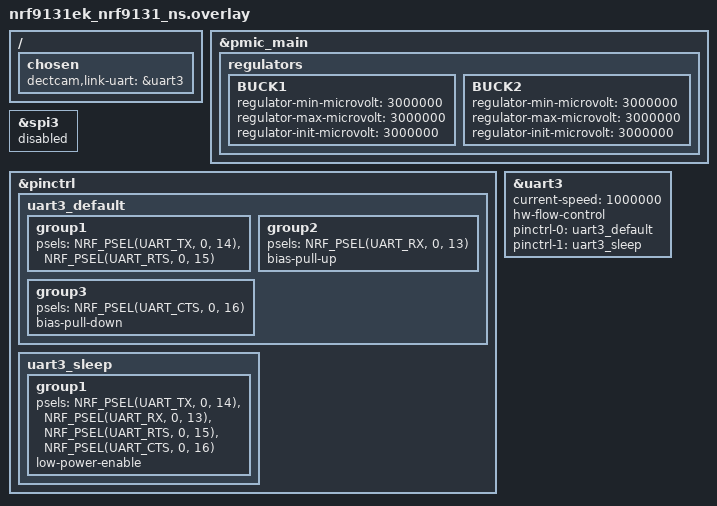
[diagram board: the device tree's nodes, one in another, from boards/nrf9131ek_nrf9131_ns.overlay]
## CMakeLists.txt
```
cmake_minimum_required(VERSION 3.20.0)

find_package(Zephyr REQUIRED HINTS $ENV{ZEPHYR_BASE})

project(dect_cam_tx)

target_sources(app PRIVATE
    src/main.c
    src/radio.c
    src/uart_in.c
    src/camctl.c
    src/ctrl.c
)

# Shared protocol / config headers live one level up, outside this app.
target_include_directories(app PRIVATE ${CMAKE_CURRENT_SOURCE_DIR}/../common)
```

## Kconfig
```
# rsource, not source: plain `source` resolves against $srctree (ZEPHYR_BASE),
# whereas rsource is relative to this file, which is what we want for a
# sibling directory.
rsource "../common/Kconfig.dectcam"

menu "DECT camera transmitter"

config DECTCAM_TX_UART_BAUD
	int "Baud rate of the link from the camera board"
	default 1000000
	help
	  Must match CONFIG_DECTCAM_UART_BAUD on the ESP32. 1 Mbaud is the
	  nRF9151 UARTE maximum.

config DECTCAM_TX_RING_SIZE
	int "Input ring buffer size (bytes)"
	default 8192
	help
	  Buffers packets arriving from the ESP32 while the radio is busy.

	  Deliberately modest: this is live video, so a deep buffer only adds
	  latency. When it overflows the oldest bytes are discarded and the
	  decoder resynchronises on the next packet magic.

config DECTCAM_TX_LBT
	bool "Listen before talk"
	default n
	help
	  Measure channel RSSI before each transmission and skip the slot if
	  the channel is busy.

	  Streaming video is a near-continuous transmit duty cycle, which the
	  NCS DECT samples make no attempt to regulate. Enabling this is a
	  step towards the channel-access behaviour ETSI EN 301 406-2 expects,
	  at the cost of throughput and jitter.

	  It is NOT a completeness claim: this is lab equipment and confirming
	  local compliance remains the operator's responsibility.

config DECTCAM_TX_LBT_THRESHOLD
	int "LBT RSSI threshold (dBm)"
	default -70
	depends on DECTCAM_TX_LBT
	help
	  Channel is considered busy above this level.

config DECTCAM_TX_TEST_PATTERN
	bool "Transmit a generated test pattern instead of UART input"
	default n
	help
	  Emits synthetic frames without needing the ESP32 connected, so the
	  radio link can be brought up and measured on its own. Pairs with the
	  receiver and the PC viewer to validate everything except the camera.

config DECTCAM_TX_TEST_PATTERN_SIZE
	int "Test pattern frame size (bytes)"
	default 6000
	depends on DECTCAM_TX_TEST_PATTERN

config DECTCAM_TX_TEST_PATTERN_FPS
	int "Test pattern frame rate"
	default 10
	depends on DECTCAM_TX_TEST_PATTERN

endmenu

menu "Zephyr Kernel"
source "Kconfig.zephyr"
endmenu
```

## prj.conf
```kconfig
# DECT camera transmitter

CONFIG_TFM_PROFILE_TYPE_MINIMAL=y

# Modem + DECT NR+ PHY
CONFIG_NRF_MODEM_LIB=y
CONFIG_NRF_MODEM_LINK_BINARY_DECT_PHY=y
CONFIG_MODEM_ANTENNA=n

CONFIG_HWINFO=y

# UART link from the camera board. Async so EasyDMA does the work; a polled or
# interrupt-per-byte driver cannot keep up with 1 Mbaud alongside the radio.
CONFIG_SERIAL=y
CONFIG_UART_ASYNC_API=y
CONFIG_RING_BUFFER=y

# The link uart MUST be async, uart0 MUST stay interrupt-driven for the shell.
# The per-instance switches carry the instance number in the symbol name, so
# they live in boards/<board>.conf next to the overlay that chooses the
# instance: the DK uses uart2, the EK uart3.

CONFIG_LOG=y
CONFIG_LOG_BUFFER_SIZE=4096
# Without this Zephyr renders every %f in a log message as the literal
# "*float*", which silently destroys all the rate statistics.
CONFIG_CBPRINTF_FP_SUPPORT=y
# Immediate, not deferred.
#
# With deferred logging plus the shell enabled, nothing at all reached a
# passively captured console -- output only appeared in response to typed
# input. That blinded the whole bring-up: an error at startup was invisible
# and looked like a wiring fault for hours.
#
# Immediate mode costs some latency in the logging call itself, which is an
# easy trade for being able to see what the board is doing.
CONFIG_LOG_MODE_IMMEDIATE=y

# Shell on VCOM0, used to reach the camera over the uart2 back-channel.
#
# The camera board has a console of its own, so this is a convenience rather
# than a necessity: it puts the camera controls on the same terminal as the
# radio statistics, and opening the camera's own port resets it, which throws
# away whatever was set at runtime.
CONFIG_SHELL=y
CONFIG_SHELL_STACK_SIZE=2048
CONFIG_SHELL_PROMPT_UART="dectcam-tx:~$ "
CONFIG_SHELL_CMD_BUFF_SIZE=128
# Route logs through the plain UART backend, NOT through the shell.
#
# With CONFIG_SHELL_LOG_BACKEND=y the periodic statistics stopped appearing on
# a passively captured console -- the shell only emitted output in response to
# input. That is fine interactively but useless when a script is watching the
# port, which is how this project is debugged.
CONFIG_SHELL_LOG_BACKEND=n
CONFIG_LOG_BACKEND_UART=y
# No colour escapes: the console is usually being captured with `cat`, and
# ANSI sequences make those logs painful to read.
CONFIG_SHELL_VT100_COLORS=n

CONFIG_MAIN_STACK_SIZE=4096
CONFIG_SYSTEM_WORKQUEUE_STACK_SIZE=2048

CONFIG_ASSERT=y
CONFIG_RESET_ON_FATAL_ERROR=n
```

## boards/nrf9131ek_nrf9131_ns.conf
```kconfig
# Per-instance UART switches for the nRF9131 EK, where the camera link is uart3.
#
# Instance 2 is not available here: on the nRF91 each instance number is shared
# by SPIM, SPIS, TWIM, TWIS and UARTE, and the EK spends instance 2 on i2c2 for
# the nPM1300 PMIC. Instance 3 is spent on spi3 for an external flash that the
# board already leaves disabled, so the overlay reclaims it.
#
# The nRF UARTE driver picks the mode per instance, and Kconfig says:
#     config UART_3_ASYNC
#         depends on UART_ASYNC_API && !UART_3_INTERRUPT_DRIVEN
#         default y
#
# Enabling the shell turns on CONFIG_UART_INTERRUPT_DRIVEN, which defaults
# UART_3_INTERRUPT_DRIVEN to y and therefore silently disables async on the
# link uart. uart_callback_set() then returns -ENOSYS, uart_in_init() fails and
# main() halts -- while the shell keeps answering from its own thread, so the
# board looks perfectly healthy. That cost a long debugging session on the DK.
CONFIG_UART_3_INTERRUPT_DRIVEN=n
CONFIG_UART_3_ASYNC=y
```

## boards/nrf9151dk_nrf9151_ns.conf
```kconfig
# Per-instance UART switches for the nRF9151 DK, where the camera link is uart2.
#
# These cannot live in prj.conf: the symbol name carries the instance number,
# and the nRF9131 EK has to use uart3 because instance 2 is its PMIC i2c.
#
# The nRF UARTE driver picks the mode per instance, and Kconfig says:
#     config UART_2_ASYNC
#         depends on UART_ASYNC_API && !UART_2_INTERRUPT_DRIVEN
#         default y
#
# Enabling the shell turns on CONFIG_UART_INTERRUPT_DRIVEN, which defaults
# UART_2_INTERRUPT_DRIVEN to y and therefore silently disables async on uart2.
# uart_callback_set() then returns -ENOSYS, uart_in_init() fails and main()
# halts -- while the shell keeps answering from its own thread, so the board
# looks perfectly healthy. That cost a long debugging session.
CONFIG_UART_2_INTERRUPT_DRIVEN=n
CONFIG_UART_2_ASYNC=y
```

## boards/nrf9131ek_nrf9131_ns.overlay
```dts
/*
 * Transmitter on the nRF9131 EK (PCA10165): uart3 routed to the left header
 * for the ESP32-S3 camera link.
 *
 *   P0.13 = RX  (from ESP32-S3 GPIO42)
 *   P0.14 = TX  (to   ESP32-S3 GPIO21)
 *   P0.15 = RTS (to   ESP32-S3 GPIO41 / CTS)
 *   P0.16 = CTS (from ESP32-S3 GPIO47 / RTS)
 *
 * One connector only, as required. The EK breaks out P0.13 to P0.31 on the
 * left header and P0.00 to P0.12 on the right, and the left header carries a
 * GND of its own between P0.13 and P0.14 -- so the whole link, ground
 * included, lands on one side of the board.
 *
 * These four are adjacent and genuinely unused: the board's device tree spends
 * P0.17 and P0.23 to P0.25 on VCOM1, P0.20 to P0.22 and P0.26 on spi3, P0.28
 * on the button and P0.29 to P0.31 on the LEDs. That leaves P0.13 to P0.16,
 * P0.18, P0.19 and P0.27 free on this header; the first four are contiguous.
 *
 * The ESP32-S3 side is unchanged from the nRF9151 DK wiring. Only the pin
 * numbers at this end move, which is the point of keeping this in an overlay.
 *
 * Why uart3 and not uart2 as on the DK
 * ------------------------------------
 * On the nRF91 each peripheral instance number is shared by SPIM, SPIS, TWIM,
 * TWIS and UARTE, so only one of them can exist at a time. Instance 2 is taken
 * here by i2c2, which is how the nPM1300 PMIC is reached, and the PMIC powers
 * the board. Instance 3 is taken by spi3, which exists only for an external
 * flash the board already leaves disabled, so that is the one to reclaim.
 *
 * Flow control
 * -------------
 * On the nRF UARTE, hardware flow control is a single CONFIG.HWFC bit covering
 * RTS *and* CTS -- Zephyr offers no RTS-only mode. We want RTS, so we get CTS
 * whether we like it or not.
 *
 * The pull-down on CTS is deliberate, as on the DK. It costs nothing while the
 * ESP32 drives the line, and if that wire is ever missing the input reads as
 * asserted and the transmitter keeps working, rather than floating and
 * behaving unpredictably.
 *
 * VDD_IO raised to 3.0 V
 * -----------------------
 * The board ships with both nPM1300 buck outputs pinned to 1.8 V, which is
 * fine for the video direction (ESP32 3.3 V into a 1.8 V input, clamped safely
 * by the 1 kOhm series resistors) but not for the return path: the ESP32-S3
 * needs 0.75 x 3.3 V = 2.475 V to read a logic high, and 1.8 V never reaches
 * that. With the camera unplugged, measured on the header VDD pin: 1.8 V at
 * the board's default, 3.0 V with the override below.
 *
 * Both BUCK1 and BUCK2 are moved together. Neither is named, labelled, or
 * connected to a documented consumer anywhere in the board's device tree, so
 * there is no way to tell which one is VDD_IO from the files alone; moving
 * only one risks leaving the SiP under-supplied on whichever rail was guessed
 * wrong. 3.0 V rather than the driver's 3.3 V ceiling matches what the nRF9151
 * DK already runs at and what the ESP32-S3 side already tolerates, keeping a
 * margin to the nPM1300's actual maximum instead of testing at it.
 *
 * This changes the level on every pin fed by this rail, uart3 included, which
 * is the point: it moves this board's camera link onto the same 3.0 V regime
 * as the DK, so the same wiring notes apply unchanged -- the two series
 * resistors on the ESP32-to-nRF lines stay mandatory. See docs/wiring.md.
 */

&pmic_main {
	regulators {
		BUCK1 {
			regulator-min-microvolt = <3000000>;
			regulator-max-microvolt = <3000000>;
			regulator-init-microvolt = <3000000>;
		};

		BUCK2 {
			regulator-min-microvolt = <3000000>;
			regulator-max-microvolt = <3000000>;
			regulator-init-microvolt = <3000000>;
		};
	};
};

/ {
	chosen {
		/* Which instance carries the camera link, so the source does not
		 * have to know. The two boards cannot agree on a number. */
		dectcam,link-uart = &uart3;
	};
};

/* Frees instance 3 for uart3. Only the external flash used it, and that flash
 * is already disabled in the board's device tree. */
&spi3 {
	status = "disabled";
};

&pinctrl {
	uart3_default: uart3_default {
		group1 {
			psels = <NRF_PSEL(UART_TX, 0, 14)>,
				<NRF_PSEL(UART_RTS, 0, 15)>;
		};
		group2 {
			psels = <NRF_PSEL(UART_RX, 0, 13)>;
			bias-pull-up;
		};
		group3 {
			/* Driven by the ESP32-S3; pull-down is the safe fallback. */
			psels = <NRF_PSEL(UART_CTS, 0, 16)>;
			bias-pull-down;
		};
	};

	uart3_sleep: uart3_sleep {
		group1 {
			psels = <NRF_PSEL(UART_TX, 0, 14)>,
				<NRF_PSEL(UART_RX, 0, 13)>,
				<NRF_PSEL(UART_RTS, 0, 15)>,
				<NRF_PSEL(UART_CTS, 0, 16)>;
			low-power-enable;
		};
	};
};

&uart3 {
	status = "okay";
	current-speed = <1000000>;
	hw-flow-control;
	pinctrl-0 = <&uart3_default>;
	pinctrl-1 = <&uart3_sleep>;
	pinctrl-names = "default", "sleep";
};
```

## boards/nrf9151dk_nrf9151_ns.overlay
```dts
/*
 * Transmitter: uart2 routed to the Arduino header for the ESP32-S3 camera link.
 *
 *   P0.02 = Arduino D2 = RX  (from ESP32-S3 GPIO42)
 *   P0.03 = Arduino D3 = TX  (to   ESP32-S3 GPIO21)
 *   P0.06 = Arduino D6 = RTS (to   ESP32-S3 GPIO41 / CTS)
 *   P0.07 = Arduino D7 = CTS (from ESP32-S3 GPIO47 / RTS)
 *
 * uart1 is not used: nrf9151dk_nrf9151_ns.dts disables it because TF-M claims
 * it for secure logging. uart2 is free and the nRF91 pin matrix lets us put
 * it on any pad.
 *
 * P0.00/01/04/05 are LEDs and P0.08/09/18/19 are buttons, so P0.02/03/06/07
 * are the free Arduino-header pins.
 *
 * Flow control
 * -------------
 * On the nRF UARTE, hardware flow control is a single CONFIG.HWFC bit covering
 * RTS *and* CTS -- Zephyr offers no RTS-only mode (see UARTE_NRF_CONFIG in
 * uart_nrfx_uarte.c). We want RTS, so we get CTS whether we like it or not.
 *
 * The previous camera board, an AI-Thinker ESP32-CAM, had no spare boot-safe
 * output pin to drive our CTS, so CTS was parked on P0.07 with an internal
 * pull-down: permanently "clear to send", with D7 required to stay
 * unconnected. The ESP32-S3 has the pin, so this is now a real signal.
 *
 * The pull-down is kept deliberately. It costs nothing while the ESP32 drives
 * the line, and if that wire is ever missing the input reads as asserted and
 * the transmitter keeps working, rather than floating and behaving
 * unpredictably.
 */

/ {
	chosen {
		/* Which instance carries the camera link, so the source does not
		 * have to know. The nRF9131 EK cannot use uart2 -- instance 2 is
		 * its PMIC i2c -- so this is a board property, not an
		 * application one. */
		dectcam,link-uart = &uart2;
	};
};

&pinctrl {
	uart2_default: uart2_default {
		group1 {
			psels = <NRF_PSEL(UART_TX, 0, 3)>,
				<NRF_PSEL(UART_RTS, 0, 6)>;
		};
		group2 {
			psels = <NRF_PSEL(UART_RX, 0, 2)>;
			bias-pull-up;
		};
		group3 {
			/* Driven by the ESP32-S3; pull-down is the safe fallback. */
			psels = <NRF_PSEL(UART_CTS, 0, 7)>;
			bias-pull-down;
		};
	};

	uart2_sleep: uart2_sleep {
		group1 {
			psels = <NRF_PSEL(UART_TX, 0, 3)>,
				<NRF_PSEL(UART_RX, 0, 2)>,
				<NRF_PSEL(UART_RTS, 0, 6)>,
				<NRF_PSEL(UART_CTS, 0, 7)>;
			low-power-enable;
		};
	};
};

&uart2 {
	status = "okay";
	current-speed = <1000000>;
	hw-flow-control;
	pinctrl-0 = <&uart2_default>;
	pinctrl-1 = <&uart2_sleep>;
	pinctrl-names = "default", "sleep";
};
```

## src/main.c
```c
/*
 * main.c - DECT NR+ camera link, transmitter.
 *
 * SPDX-License-Identifier: Apache-2.0
 *
 * Reads dectcam packets from the camera board over uart2 and retransmits each one
 * verbatim as a DECT NR+ PDC. The packet format is chosen so that exactly one
 * packet fits one transport block, so this side never has to parse or
 * re-fragment anything: it is a pure pump.
 *
 * See docs/architecture.md for the whole picture.
 */

#include <zephyr/kernel.h>
#include <zephyr/logging/log.h>
#include <zephyr/drivers/gpio.h>

#include "radio.h"
#include "uart_in.h"
#include "ctrl.h"
#include "dectcam_cfg.h"

LOG_MODULE_REGISTER(dectcam_tx, CONFIG_DECTCAM_LOG_LEVEL);

/* LED0 = radio up, LED1 = TX activity. */
static const struct gpio_dt_spec led_up = GPIO_DT_SPEC_GET(DT_ALIAS(led0), gpios);
static const struct gpio_dt_spec led_tx = GPIO_DT_SPEC_GET(DT_ALIAS(led1), gpios);

static uint8_t pkt_buf[DECTCAM_MAX_PACKET];

static void leds_init(void)
{
	if (gpio_is_ready_dt(&led_up)) {
		gpio_pin_configure_dt(&led_up, GPIO_OUTPUT_INACTIVE);
	}
	if (gpio_is_ready_dt(&led_tx)) {
		gpio_pin_configure_dt(&led_tx, GPIO_OUTPUT_INACTIVE);
	}
}

#if CONFIG_DECTCAM_TX_TEST_PATTERN
/*
 * Synthetic frames so the radio link can be characterised without the camera
 * or the ESP32 attached. The payload is a counting pattern, which makes any
 * corruption obvious in a hex dump at the far end.
 */
#include "dectcam_proto.h"

static int send_test_frame(uint16_t frame_id)
{
	const uint16_t frag_payload = DECTCAM_FRAG_PAYLOAD;
	const uint16_t total = CONFIG_DECTCAM_TX_TEST_PATTERN_SIZE;
	const uint16_t nfrag = (total + frag_payload - 1) / frag_payload;
	static uint8_t body[DECTCAM_MAX_PAYLOAD];
	int sent = 0;

	for (uint16_t i = 0; i < nfrag; i++) {
		const uint16_t chunk =
			MIN(frag_payload, (uint16_t)(total - i * frag_payload));

		for (uint16_t k = 0; k < chunk; k++) {
			body[k] = (uint8_t)(frame_id + i + k);
		}

		const size_t plen = dectcam_encode(pkt_buf, sizeof(pkt_buf),
						   DECTCAM_TYPE_JPEG_FRAG, frame_id, i, nfrag,
						   body, chunk);

		if (plen == 0 || radio_tx(pkt_buf, plen) != 0) {
			return sent;
		}
		sent++;
	}
	return sent;
}
#endif

int main(void)
{
	LOG_INF("DECT camera transmitter starting");

	leds_init();

	if (radio_init() != 0) {
		LOG_ERR("radio init failed; halting");
		return -EIO;
	}
	radio_set_ctrl_cb(ctrl_on_packet);
	gpio_pin_set_dt(&led_up, 1);

#if !CONFIG_DECTCAM_TX_TEST_PATTERN
	if (uart_in_init() != 0) {
		LOG_ERR("uart init failed; halting");
		return -EIO;
	}
#else
	LOG_WRN("TEST PATTERN mode: uart input is not used");
#endif

	int64_t last_stats = k_uptime_get();
	uint32_t tx_since = 0;
	uint64_t bytes_since = 0;

#if CONFIG_DECTCAM_TX_TEST_PATTERN
	uint16_t frame_id = 0;
	const int64_t period_ms = 1000 / CONFIG_DECTCAM_TX_TEST_PATTERN_FPS;
#endif

	for (;;) {
#if CONFIG_DECTCAM_TX_TEST_PATTERN
		const int64_t t0 = k_uptime_get();
		int n = send_test_frame(frame_id++);

		tx_since += n;
		bytes_since += (uint64_t)n * DECTCAM_TBS_BYTES;
		gpio_pin_toggle_dt(&led_tx);

		const int64_t spent = k_uptime_get() - t0;

		if (spent < period_ms) {
			k_msleep(period_ms - spent);
		}
#else
		/*
		 * Listen for control before touching the radio for video, so
		 * the receive window never lands in the middle of a burst.
		 */
		ctrl_poll();

		/*
		 * Slip any pending acknowledgement into the stream. It is an
		 * ordinary packet as far as everything downstream is
		 * concerned, and it rides the direction that already works.
		 */
		{
			uint8_t ack[DECTCAM_CTRL_LEN + DECTCAM_OVERHEAD];
			const size_t n = ctrl_pending_ack(ack, sizeof(ack));

			if (n > 0) {
				radio_tx(ack, n);
			}
		}

		/*
		 * Announce the radio settings once a second, for the same
		 * reason the camera announces its own: they change at run time
		 * now, and a viewer that attaches later has no other way to
		 * learn where the link ended up.
		 */
		{
			static int64_t last_cfg;
			const int64_t t = k_uptime_get();

			if (t - last_cfg >= 1000) {
				struct radio_cfg rc;
				struct dectcam_radio_cfg body;
				uint8_t buf[DECTCAM_RADIO_CFG_LEN + DECTCAM_OVERHEAD];
				uint8_t packed[DECTCAM_RADIO_CFG_LEN];

				last_cfg = t;
				radio_get_cfg(&rc);
				body.carrier = rc.carrier;
				body.mcs = rc.mcs;
				body.tx_power = rc.tx_power;
				body.subslots = rc.subslots;
				body.reserved = 0;
				body.frag_payload = rc.frag_payload;
				dectcam_radio_cfg_pack(packed, &body);

				const size_t n = dectcam_encode(
					buf, sizeof(buf), DECTCAM_TYPE_RADIO_CFG, 0, 0, 0,
					packed, sizeof(packed));

				if (n > 0) {
					radio_tx(buf, n);
				}
			}
		}

		int len = uart_in_get_packet(pkt_buf, sizeof(pkt_buf), 100);

		if (len > 0) {
			if (radio_tx(pkt_buf, len) == 0) {
				tx_since++;
				bytes_since += len;
				/*
				 * Toggling per packet would be a blur; every
				 * 16 gives a visible flicker that tracks
				 * activity.
				 */
				if ((tx_since & 0x0f) == 0) {
					gpio_pin_toggle_dt(&led_tx);
				}
			}
		}
#endif

#if CONFIG_DECTCAM_STATS_INTERVAL_MS > 0
		const int64_t now = k_uptime_get();

		if (now - last_stats >= CONFIG_DECTCAM_STATS_INTERVAL_MS) {
			const double secs = (now - last_stats) / 1000.0;
			struct radio_stats rs;

			radio_get_stats(&rs);

#if CONFIG_DECTCAM_TX_TEST_PATTERN
			LOG_INF("tx %.1f pkt/s, %.1f kB/s | ok %u err %u lbt_busy %u",
				tx_since / secs, bytes_since / secs / 1000.0, rs.tx_ok,
				rs.tx_err, rs.tx_lbt_busy);
#else
			struct uart_in_stats us;

			uart_in_get_stats(&us);
			LOG_INF("tx %.1f pkt/s, %.1f kB/s | radio ok %u err %u lbt %u | "
				"uart pkt %u crc %u resync %u ovr %u",
				tx_since / secs, bytes_since / secs / 1000.0, rs.tx_ok,
				rs.tx_err, rs.tx_lbt_busy, us.packets, us.crc_err, us.resyncs,
				us.overruns);
#endif
			tx_since = 0;
			bytes_since = 0;
			last_stats = now;
		}
#endif
	}

	return 0;
}
```

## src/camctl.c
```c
/*
 * camctl.c - shell command that forwards text to the camera board.
 *
 * SPDX-License-Identifier: Apache-2.0
 *
 * The uart link to the camera is full duplex: the camera sends video packets
 * on its TX line, and its RX line (our P0.03 -> ESP32-S3 GPIO21) would
 * otherwise be idle. This puts it to work as a control channel, so camera
 * parameters can be changed from the transmitter's own console.
 *
 * The camera board has a console of its own, so this is a convenience rather
 * than a necessity -- but a real one: it puts the camera controls on the same
 * terminal as the radio statistics, and opening the camera's own port resets
 * the board, which throws away whatever was set at runtime.
 *
 * No reply comes back: the return direction carries the video stream and must
 * not be polluted with text. Confirmation arrives instead as a FRAME_META
 * packet, which the PC viewer displays.
 */

#include <zephyr/kernel.h>
#include <zephyr/shell/shell.h>
#include <zephyr/device.h>
#include <zephyr/drivers/uart.h>
#include <zephyr/logging/log.h>

#include "radio.h"
#include "uart_in.h"
#include "camctl.h"

LOG_MODULE_DECLARE(dectcam_tx, CONFIG_DECTCAM_LOG_LEVEL);

/*
 * The camera's resolution table, in the order the wire protocol indexes it.
 * Must match s_sizes[] in the camera firmware and RESOLUTIONS in the viewer;
 * the protocol self-tests pin the order down on both of those.
 */
static const char *const res_names[] = {
	"qqvga", "qcif", "hqvga", "qvga", "cif", "hvga", "vga", "svga",
};

const char *camctl_res_name(uint8_t index)
{
	if (index >= ARRAY_SIZE(res_names)) {
		return NULL;
	}
	return res_names[index];
}

/*
 * Put one line on the wire.
 *
 * Delegated to uart_in, which owns the device and its callback. This used to
 * use uart_poll_out() directly, on the reasoning that a dozen bytes at 1 Mbaud
 * is too short to be worth DMA. That was wrong for a subtler reason: the
 * receive side holds the UART open with the async API, and poll_out alongside
 * it loses characters. "cam fps 15" reached the camera as "cam fps 1".
 */
static int write_line(const char *line)
{
	return uart_in_send_line(line);
}

static int send_line(const struct shell *sh, const char *line)
{
	int err = write_line(line);

	if (err == -ENODEV) {
		shell_error(sh, "link uart not ready");
	}
	return err;
}

int camctl_send_res(uint8_t index)
{
	const char *name = camctl_res_name(index);
	char line[32];

	if (name == NULL) {
		return -EINVAL;
	}
	snprintk(line, sizeof(line), "cam res %s", name);
	LOG_INF("camera: %s", line);
	return write_line(line);
}

int camctl_send_fps(uint8_t fps)
{
	char line[32];

	if (fps < 1 || fps > 30) {
		return -EINVAL;
	}
	snprintk(line, sizeof(line), "cam fps %u", fps);
	LOG_INF("camera: %s", line);
	return write_line(line);
}

int camctl_send_quality(uint8_t q)
{
	char line[32];

	if (q < 4 || q > 63) {
		return -EINVAL;
	}
	snprintk(line, sizeof(line), "cam quality %u", q);
	LOG_INF("camera: %s", line);
	return write_line(line);
}

static int cmd_cam(const struct shell *sh, size_t argc, char **argv)
{
	char line[96];
	size_t off = 0;

	if (argc < 2) {
		shell_print(sh, "usage: cam <res|quality|fps|vflip|hmirror|pause|resume|info> "
				"[value]");
		shell_print(sh, "  res      qqvga qcif hqvga qvga cif hvga vga svga");
		shell_print(sh, "  quality  4..63 (LOWER is better quality, bigger frames)");
		shell_print(sh, "  fps      1..30");
		shell_print(sh, "");
		shell_print(sh, "The camera does not reply on this wire; watch the viewer's");
		shell_print(sh, "FRAME_META readout to confirm the change took effect.");
		return -EINVAL;
	}

	/* Rebuild "cam <args...>" for the far end. */
	off = snprintk(line, sizeof(line), "cam");
	for (size_t i = 1; i < argc; i++) {
		int n = snprintk(&line[off], sizeof(line) - off, " %s", argv[i]);

		if (n < 0 || (size_t)n >= sizeof(line) - off) {
			shell_error(sh, "command too long");
			return -EINVAL;
		}
		off += n;
	}

	if (send_line(sh, line) != 0) {
		return -EIO;
	}
	shell_print(sh, "sent to camera: %s", line);
	return 0;
}

static int cmd_camraw(const struct shell *sh, size_t argc, char **argv)
{
	if (argc < 2) {
		shell_print(sh, "usage: camraw <text>   (sent verbatim, newline appended)");
		return -EINVAL;
	}

	char line[96];
	size_t off = 0;

	for (size_t i = 1; i < argc; i++) {
		int n = snprintk(&line[off], sizeof(line) - off, i == 1 ? "%s" : " %s", argv[i]);

		if (n < 0 || (size_t)n >= sizeof(line) - off) {
			shell_error(sh, "command too long");
			return -EINVAL;
		}
		off += n;
	}

	if (send_line(sh, line) != 0) {
		return -EIO;
	}
	shell_print(sh, "sent to camera: %s", line);
	return 0;
}

/*
 * On-demand status. Deliberately independent of the logging subsystem: when
 * logs are misconfigured or a capture is passive, this still answers.
 */
static int cmd_dectstat(const struct shell *sh, size_t argc, char **argv)
{
	ARG_UNUSED(argc);
	ARG_UNUSED(argv);

	struct radio_stats rs;
	struct uart_in_stats us;

	radio_get_stats(&rs);
	uart_in_get_stats(&us);

	shell_print(sh, "device id     : %u", radio_device_id());
	shell_print(sh, "-- uart from camera --");
	shell_print(sh, "  packets     : %u", us.packets);
	shell_print(sh, "  bytes       : %llu", (unsigned long long)us.bytes);
	shell_print(sh, "  crc errors  : %u", us.crc_err);
	shell_print(sh, "  resyncs     : %u", us.resyncs);
	shell_print(sh, "  overruns    : %u", us.overruns);
	shell_print(sh, "-- radio --");
	shell_print(sh, "  tx ok       : %u", rs.tx_ok);
	shell_print(sh, "  tx err      : %u", rs.tx_err);
	shell_print(sh, "  lbt busy    : %u", rs.tx_lbt_busy);
	shell_print(sh, "  tx bytes    : %llu", (unsigned long long)rs.tx_bytes);

	if (us.bytes == 0) {
		shell_warn(sh, "");
		shell_warn(sh, "No bytes at all from the camera. Check that it is powered");
		shell_warn(sh, "and that GPIO42 reaches P0.02 (Arduino D2).");
		shell_warn(sh, "If the camera reports 'link stalled', it is being held off");
		shell_warn(sh, "by flow control: check GPIO41 against P0.06 (Arduino D6).");
	}
	return 0;
}

SHELL_CMD_ARG_REGISTER(cam, NULL, "Control the camera over the uart back-channel",
		       cmd_cam, 1, 8);
SHELL_CMD_ARG_REGISTER(camraw, NULL, "Send a raw line to the camera", cmd_camraw, 1, 8);
SHELL_CMD_REGISTER(dectstat, NULL, "Transmitter link and radio counters", cmd_dectstat);
```

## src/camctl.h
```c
/*
 * camctl.h - forward commands to the camera over the UART back-channel.
 *
 * SPDX-License-Identifier: Apache-2.0
 *
 * The same wire that carries video also carries text the other way. These
 * entry points exist so that control telegrams arriving over the air can be
 * passed on without going through the shell.
 *
 * Nothing comes back: the return direction is the video stream and must stay
 * clean. Confirmation reaches the operator as a FRAME_META packet announcing
 * the camera's new settings, which the viewer displays.
 */

#ifndef DECTCAM_TX_CAMCTL_H
#define DECTCAM_TX_CAMCTL_H

#include <stdint.h>

/*
 * Resolution by index into the camera's own table. An index is used rather
 * than a name because it is what travels on the wire; the order is fixed and
 * is checked by the protocol self-tests on both sides.
 */
int camctl_send_res(uint8_t index);

/* 1..30. */
int camctl_send_fps(uint8_t fps);

/* 4..63, lower is better quality and larger frames. */
int camctl_send_quality(uint8_t q);

/* The resolution names, in wire order. NULL if the index is out of range. */
const char *camctl_res_name(uint8_t index);

#endif /* DECTCAM_TX_CAMCTL_H */
```

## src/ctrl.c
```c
/*
 * ctrl.c - control telegrams received over the air, transmitter side.
 *
 * SPDX-License-Identifier: Apache-2.0
 *
 * The operator drives everything from the PC, which is attached to the
 * receiver. Commands therefore travel against the video: PC -> receiver ->
 * air -> here. Anything aimed at the camera is passed on over the UART
 * back-channel that already exists for that purpose.
 *
 * Two things shape the design:
 *
 *   - There is one radio, and it is busy pushing video. Listening means not
 *     transmitting, so the window is short and infrequent, and the sender has
 *     to repeat a telegram until one lands. Repetition is made safe by the
 *     sequence number: a telegram already acted on is counted and ignored.
 *
 *   - Changing the carrier moves the link itself. If only one end moves, the
 *     link is gone and no further command can reach anyone. That case is
 *     handled by moving on trial and returning automatically -- see below.
 */

#include <zephyr/kernel.h>
#include <zephyr/logging/log.h>

#include "ctrl.h"
#include "radio.h"
#include "camctl.h"
#include "dectcam_cfg.h"

LOG_MODULE_DECLARE(dectcam_tx, CONFIG_DECTCAM_LOG_LEVEL);

/*
 * How often to stop transmitting and listen, and for how long.
 *
 * 30 ms out of every 200 costs 15 % of the air time. That sounds like a lot,
 * but the link runs at about half the capacity it has, so it costs no frames
 * in practice -- and it has to be this generous: the far end sends its copies
 * 25 ms apart, so a window narrower than that could fall between two of them
 * and hear nothing at all.
 */
#define LISTEN_PERIOD_MS 200
#define LISTEN_MS        30

/*
 * Carrier change, and why it is done the way it is.
 *
 * The receiver announces the new carrier on the OLD one, then moves. This side
 * moves as soon as it has acknowledged. From that moment the link is unproven:
 * if the receiver never arrives -- wrong channel, interference, a command that
 * was corrupted into a different number -- nothing more can be said to either
 * end, and the only recovery would be a power cycle.
 *
 * So the move is on trial. The receiver confirms with CARRIER_OK once it is
 * actually seeing video on the new carrier. If that confirmation does not
 * arrive in time, this side returns to the previous carrier on its own. The
 * receiver runs the same rollback on a shorter deadline, so the two converge
 * on the old carrier rather than crossing over.
 */
#define CARRIER_TRIAL_MS 6000

static struct ctrl_stats s_stats;

/* Last sequence acted on, so repeats are free of side effects. */
static bool s_have_last_seq;
static uint8_t s_last_seq;

/*
 * Acknowledgement waiting to be slipped into the video stream.
 *
 * Repeated on a clock rather than a count, and for longer than feels
 * necessary, because of when it has to arrive: the far end transmits its
 * command as a one-second burst, and while it is transmitting it is deaf. An
 * acknowledgement sent promptly -- which is what happens, since the command is
 * applied on the first copy that lands -- is therefore usually sent straight
 * into that deafness. Repeating for well past the end of the burst is what
 * makes it land.
 */
#define ACK_REPEAT_MS 150
#define ACK_FOR_MS    2500

static bool s_ack_pending;
static uint8_t s_ack_seq;
static uint8_t s_ack_status;
static int64_t s_ack_until;
static int64_t s_ack_next;

/* Carrier trial state. */
static bool s_carrier_trial;
static uint16_t s_carrier_previous;
static int64_t s_carrier_deadline;

static int64_t s_next_listen;

static void queue_ack(uint8_t seq, uint8_t status)
{
	const int64_t now = k_uptime_get();

	s_ack_pending = true;
	s_ack_seq = seq;
	s_ack_status = status;
	s_ack_until = now + ACK_FOR_MS;
	s_ack_next = now;
}

static uint8_t apply(uint8_t opcode, uint32_t arg)
{
	switch (opcode) {
	case DECTCAM_CTRL_SET_TX_POWER:
		return radio_set_tx_power((uint8_t)arg) == 0
			       ? DECTCAM_ACK_OK
			       : DECTCAM_ACK_BAD_ARG;

	case DECTCAM_CTRL_SET_MCS:
		return radio_set_mcs((uint8_t)arg) == 0
			       ? DECTCAM_ACK_OK
			       : DECTCAM_ACK_BAD_ARG;

	case DECTCAM_CTRL_SET_CARRIER: {
		struct radio_cfg cfg;

		radio_get_cfg(&cfg);
		if (arg == 0 || arg > 0xffff) {
			return DECTCAM_ACK_BAD_ARG;
		}
		if ((uint16_t)arg == cfg.carrier) {
			return DECTCAM_ACK_OK;
		}

		s_carrier_previous = cfg.carrier;
		if (radio_set_carrier((uint16_t)arg) != 0) {
			return DECTCAM_ACK_FAILED;
		}
		s_carrier_trial = true;
		s_carrier_deadline = k_uptime_get() + CARRIER_TRIAL_MS;
		s_stats.carrier_moves++;
		LOG_WRN("carrier %u -> %u on trial; returning in %d ms unless confirmed",
			s_carrier_previous, (uint16_t)arg, CARRIER_TRIAL_MS);
		return DECTCAM_ACK_OK;
	}

	case DECTCAM_CTRL_CARRIER_OK:
		if (s_carrier_trial) {
			s_carrier_trial = false;
			LOG_INF("carrier confirmed by the receiver");
		}
		return DECTCAM_ACK_OK;

	/* Everything below belongs to the camera, not the radio. */
	case DECTCAM_CTRL_SET_RES:
		return camctl_send_res((uint8_t)arg) == 0 ? DECTCAM_ACK_OK
							  : DECTCAM_ACK_BAD_ARG;
	case DECTCAM_CTRL_SET_FPS:
		return camctl_send_fps((uint8_t)arg) == 0 ? DECTCAM_ACK_OK
							  : DECTCAM_ACK_BAD_ARG;
	case DECTCAM_CTRL_SET_QUALITY:
		return camctl_send_quality((uint8_t)arg) == 0 ? DECTCAM_ACK_OK
							      : DECTCAM_ACK_BAD_ARG;

	case DECTCAM_CTRL_NOP:
		return DECTCAM_ACK_OK;

	default:
		return DECTCAM_ACK_UNSUPP;
	}
}

/*
 * Telegram waiting to be acted on.
 *
 * ctrl_on_packet() runs in the modem's event callback -- interrupt context --
 * and must do as little as possible there. Applying a telegram means writing
 * to a UART and logging, neither of which belongs in an interrupt: doing it
 * there truncated a "cam fps 15" into "cam fps 1", which the camera dutifully
 * obeyed.
 *
 * So the callback only parks the telegram, and ctrl_poll() applies it from the
 * main loop. One slot is enough: telegrams arrive at human speed and repeats
 * of the same one are collapsed by the sequence check anyway.
 */
static volatile bool s_inbox_full;
static struct dectcam_ctrl s_inbox;

void ctrl_on_packet(const uint8_t *data, size_t len)
{
	struct dectcam_pkt pkt;
	size_t consumed;

	if (dectcam_decode(data, len, &pkt, &consumed) != DECTCAM_OK) {
		return;
	}
	if (pkt.type != DECTCAM_TYPE_CTRL || pkt.payload_len < DECTCAM_CTRL_LEN) {
		return;
	}
	if (s_inbox_full) {
		/* Still working on the previous one; this is almost certainly a
		 * repeat of it, and the far end will send it again. */
		return;
	}

	dectcam_ctrl_unpack(pkt.payload, &s_inbox);
	s_inbox_full = true;
}

static void process_inbox(void)
{
	if (!s_inbox_full) {
		return;
	}

	const struct dectcam_ctrl c = s_inbox;

	s_inbox_full = false;

	/*
	 * A repeat of something already done. Acknowledge it again -- the
	 * previous acknowledgement evidently did not get through, or the far
	 * end would have stopped repeating -- but do not act on it twice.
	 */
	if (s_have_last_seq && c.seq == s_last_seq) {
		s_stats.duplicates++;
		queue_ack(c.seq, DECTCAM_ACK_OK);
		return;
	}

	const uint8_t status = apply(c.opcode, c.arg32);

	s_have_last_seq = true;
	s_last_seq = c.seq;

	if (status == DECTCAM_ACK_OK) {
		s_stats.applied++;
	} else {
		s_stats.rejected++;
		LOG_WRN("control opcode %u arg %u rejected: status %u", c.opcode,
			(unsigned)c.arg32, status);
	}
	queue_ack(c.seq, status);
}

void ctrl_poll(void)
{
	const int64_t now = k_uptime_get();

	process_inbox();

	/* Carrier trial expired without confirmation: go back. */
	if (s_carrier_trial && now >= s_carrier_deadline) {
		s_carrier_trial = false;
		s_stats.carrier_rollbacks++;
		LOG_ERR("carrier not confirmed; returning to %u", s_carrier_previous);
		radio_set_carrier(s_carrier_previous);
	}

	if (now < s_next_listen) {
		return;
	}
	s_next_listen = now + LISTEN_PERIOD_MS;

	radio_listen(LISTEN_MS);
}

size_t ctrl_pending_ack(uint8_t *out, size_t cap)
{
	if (!s_ack_pending) {
		return 0;
	}

	const int64_t now = k_uptime_get();

	if (now >= s_ack_until) {
		s_ack_pending = false;
		return 0;
	}
	if (now < s_ack_next) {
		return 0;
	}
	s_ack_next = now + ACK_REPEAT_MS;

	const size_t n = dectcam_encode_ctrl(out, cap, DECTCAM_CTRL_ACK, s_ack_seq,
					     s_ack_status);

	if (n == 0) {
		s_ack_pending = false;
	}
	return n;
}

void ctrl_get_stats(struct ctrl_stats *out)
{
	if (out) {
		*out = s_stats;
	}
}
```

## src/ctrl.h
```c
/*
 * ctrl.h - control telegrams received over the air, transmitter side.
 *
 * SPDX-License-Identifier: Apache-2.0
 */

#ifndef DECTCAM_TX_CTRL_H
#define DECTCAM_TX_CTRL_H

#include <stdbool.h>
#include <stdint.h>
#include <stddef.h>

/* Hand a packet received during a listen window to the control logic. */
void ctrl_on_packet(const uint8_t *data, size_t len);

/*
 * Give the control logic a slice of the main loop.
 *
 * Opens a listen window when one is due, applies anything that arrived, and
 * runs the carrier rollback timer. Returns the number of milliseconds the
 * caller should not transmit for, which is zero unless a window is open.
 */
void ctrl_poll(void);

/*
 * Fill `out` with the acknowledgement that is waiting to go into the video
 * stream, if any. Returns its length, or 0 when there is nothing to send.
 *
 * Acknowledgements travel with the video because that direction already
 * exists and already works; adding a second radio turnaround for them would
 * cost air time for no benefit.
 */
size_t ctrl_pending_ack(uint8_t *out, size_t cap);

struct ctrl_stats {
	uint32_t applied;
	uint32_t duplicates;   /* repeats of a telegram already acted on */
	uint32_t rejected;
	uint32_t carrier_moves;
	uint32_t carrier_rollbacks;
};

void ctrl_get_stats(struct ctrl_stats *out);

#endif /* DECTCAM_TX_CTRL_H */
```

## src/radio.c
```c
/*
 * radio.c - DECT NR+ PHY transmit wrapper.
 *
 * SPDX-License-Identifier: Apache-2.0
 *
 * Thin layer over nrf_modem_dect_phy: bring-up sequence, then one blocking
 * transmit call. Structured after the NCS hello_dect sample, which is the
 * reference for what this modem firmware accepts.
 */

#include <zephyr/kernel.h>
#include <zephyr/logging/log.h>
#include <zephyr/drivers/hwinfo.h>

#include <nrf_modem_dect_phy.h>
#include <modem/nrf_modem_lib.h>

#include "radio.h"
#include "dectcam_cfg.h"

LOG_MODULE_REGISTER(radio, CONFIG_DECTCAM_LOG_LEVEL);

BUILD_ASSERT(CONFIG_DECTCAM_CARRIER != 0,
	     "CONFIG_DECTCAM_CARRIER must be set according to local regulations");

static uint16_t s_device_id;
static struct radio_stats s_stats;
static radio_ctrl_cb_t s_ctrl_cb;

/*
 * Live radio parameters, seeded from Kconfig.
 *
 * They were compile-time constants until control from the receiver was added.
 * Keeping them in one struct makes it obvious that the transport block size
 * and the fragment size are derived quantities that must be recomputed
 * whenever the MCS moves -- getting that wrong means the modem silently
 * rejects every transmit.
 */
static struct radio_cfg s_cfg = {
	.carrier = CONFIG_DECTCAM_CARRIER,
	.mcs = CONFIG_DECTCAM_MCS,
	.tx_power = CONFIG_DECTCAM_TX_POWER,
	.subslots = CONFIG_DECTCAM_PACKET_LEN_SUBSLOTS,
	.tbs_bytes = DECTCAM_TBS_BYTES,
	.frag_payload = DECTCAM_FRAG_PAYLOAD,
};

/* Signalled when an asynchronous PHY operation finishes. */
static K_SEM_DEFINE(op_sem, 0, 1);
/* Result of the operation that just completed. */
static volatile int s_op_err;

static bool s_fatal;

#define TX_HANDLE 0u
#define RX_HANDLE 1u
#define OP_TIMEOUT K_MSEC(500)

static void handle_common(int err)
{
	s_op_err = err;
	k_sem_give(&op_sem);
}

static void dect_phy_event_handler(const struct nrf_modem_dect_phy_event *evt)
{
	switch (evt->id) {
	case NRF_MODEM_DECT_PHY_EVT_INIT:
		if (evt->init.err) {
			LOG_ERR("PHY init failed: %d", evt->init.err);
			s_fatal = true;
		}
		handle_common(evt->init.err);
		break;
	case NRF_MODEM_DECT_PHY_EVT_CONFIGURE:
		if (evt->configure.err) {
			LOG_ERR("PHY configure failed: %d", evt->configure.err);
			s_fatal = true;
		}
		handle_common(evt->configure.err);
		break;
	case NRF_MODEM_DECT_PHY_EVT_ACTIVATE:
		if (evt->activate.err) {
			LOG_ERR("PHY activate failed: %d", evt->activate.err);
			s_fatal = true;
		}
		handle_common(evt->activate.err);
		break;
	case NRF_MODEM_DECT_PHY_EVT_COMPLETED:
		handle_common(evt->op_complete.err);
		break;
	case NRF_MODEM_DECT_PHY_EVT_CANCELED:
		handle_common(evt->cancel.err);
		break;
	case NRF_MODEM_DECT_PHY_EVT_DEACTIVATE:
	case NRF_MODEM_DECT_PHY_EVT_DEINIT:
		handle_common(0);
		break;
	case NRF_MODEM_DECT_PHY_EVT_PDC:
		/*
		 * Only ever arrives during a listen window, and the only thing
		 * anyone sends this way is control. Hand it straight over; the
		 * callback must not call back into the modem.
		 */
		s_stats.ctrl_rx++;
		if (s_ctrl_cb) {
			s_ctrl_cb((const uint8_t *)evt->pdc.data, evt->pdc.len);
		}
		break;
	case NRF_MODEM_DECT_PHY_EVT_PCC:
	case NRF_MODEM_DECT_PHY_EVT_PCC_ERROR:
	case NRF_MODEM_DECT_PHY_EVT_PDC_ERROR:
		/* Nothing to do: a missed control frame is simply repeated. */
		break;

	case NRF_MODEM_DECT_PHY_EVT_REJECT:
		LOG_WRN("operation rejected");
		break;
	default:
		/* Capability/band/time/RSSI queries are not used here. */
		break;
	}
}

/* Run one bring-up step and wait for its completion event. */
static int step(const char *what, int err)
{
	if (err) {
		LOG_ERR("%s returned %d", what, err);
		return err;
	}
	if (k_sem_take(&op_sem, K_SECONDS(5)) != 0) {
		LOG_ERR("%s timed out waiting for its event", what);
		return -ETIMEDOUT;
	}
	if (s_fatal) {
		return -EIO;
	}
	return s_op_err;
}

int radio_init(void)
{
	int err;

	err = nrf_modem_lib_init();
	if (err) {
		LOG_ERR("nrf_modem_lib_init failed: %d", err);
		return err;
	}

	err = nrf_modem_dect_phy_event_handler_set(dect_phy_event_handler);
	if (err) {
		LOG_ERR("event_handler_set failed: %d", err);
		return err;
	}

	err = step("dect_phy_init", nrf_modem_dect_phy_init());
	if (err) {
		return err;
	}

	struct nrf_modem_dect_phy_config_params cfg = {
		.band_group_index = CONFIG_DECTCAM_BAND_GROUP_INDEX,
		.harq_rx_process_count = 4,
		.harq_rx_expiry_time_us = 5000000,
	};

	err = step("dect_phy_configure", nrf_modem_dect_phy_configure(&cfg));
	if (err) {
		return err;
	}

	err = step("dect_phy_activate",
		   nrf_modem_dect_phy_activate(NRF_MODEM_DECT_PHY_RADIO_MODE_LOW_LATENCY));
	if (err) {
		return err;
	}

	hwinfo_get_device_id((void *)&s_device_id, sizeof(s_device_id));

	LOG_INF("DECT PHY up: device id %u, carrier %d, MCS %d, %d subslots "
		"(%d B TBS, %d B payload, %d us air time), TX power idx %d",
		s_device_id, CONFIG_DECTCAM_CARRIER, CONFIG_DECTCAM_MCS,
		CONFIG_DECTCAM_PACKET_LEN_SUBSLOTS, DECTCAM_TBS_BYTES, DECTCAM_FRAG_PAYLOAD,
		DECTCAM_AIRTIME_US, CONFIG_DECTCAM_TX_POWER);

	return 0;
}

int radio_tx(const uint8_t *data, size_t len)
{
	if (len == 0 || len > (size_t)s_cfg.tbs_bytes) {
		return -EINVAL;
	}

	struct dectcam_phy_hdr_type1 hdr = {
		.header_format = 0,
		.packet_length_type = 0, /* subslots */
		.packet_length = (uint8_t)(s_cfg.subslots - 1),
		.short_network_id = (CONFIG_DECTCAM_NETWORK_ID & 0xff),
		.transmitter_id_hi = (s_device_id >> 8),
		.transmitter_id_lo = (s_device_id & 0xff),
		.transmit_power = s_cfg.tx_power,
		.reserved = 0,
		.df_mcs = s_cfg.mcs,
	};

	struct nrf_modem_dect_phy_tx_params tx = {
		.start_time = 0, /* as soon as possible */
		.handle = TX_HANDLE,
		.network_id = CONFIG_DECTCAM_NETWORK_ID,
		.phy_type = 0,
		.carrier = s_cfg.carrier,
		.phy_header = (union nrf_modem_dect_phy_hdr *)&hdr,
		.data = (void *)data,
		.data_size = len,
#if CONFIG_DECTCAM_TX_LBT
		.lbt_rssi_threshold_max = CONFIG_DECTCAM_TX_LBT_THRESHOLD,
		.lbt_period = NRF_MODEM_DECT_LBT_PERIOD_MAX,
#else
		/* lbt_period 0 disables listen-before-talk entirely. */
		.lbt_rssi_threshold_max = 0,
		.lbt_period = 0,
#endif
	};

	int err = nrf_modem_dect_phy_tx(&tx);

	if (err) {
		s_stats.tx_err++;
		return err;
	}

	/*
	 * Wait for completion. Without this the next call could be issued
	 * while the modem still owns `data`, and the modem would reject the
	 * operation anyway once its queue filled.
	 */
	if (k_sem_take(&op_sem, OP_TIMEOUT) != 0) {
		s_stats.tx_err++;
		LOG_WRN("TX completion timed out");
		return -ETIMEDOUT;
	}

	if (s_op_err) {
		if (s_op_err == NRF_MODEM_DECT_PHY_ERR_LBT_CHANNEL_BUSY) {
			s_stats.tx_lbt_busy++;
		} else {
			s_stats.tx_err++;
			LOG_WRN("TX completed with error %d", s_op_err);
		}
		return -EIO;
	}

	s_stats.tx_ok++;
	s_stats.tx_bytes += len;
	return 0;
}

int radio_listen(uint32_t ms)
{
	struct nrf_modem_dect_phy_rx_params rx = {
		.start_time = 0,
		.handle = RX_HANDLE,
		.network_id = CONFIG_DECTCAM_NETWORK_ID,
		.mode = NRF_MODEM_DECT_PHY_RX_MODE_CONTINUOUS,
		.rssi_interval = NRF_MODEM_DECT_PHY_RSSI_INTERVAL_OFF,
		.link_id = NRF_MODEM_DECT_PHY_LINK_UNSPECIFIED,
		.rssi_level = -60,
		.carrier = s_cfg.carrier,
		.duration = ms * NRF_MODEM_DECT_MODEM_TIME_TICK_RATE_KHZ,
		.filter.short_network_id = CONFIG_DECTCAM_NETWORK_ID & 0xff,
		.filter.is_short_network_id_used = 1,
		.filter.receiver_identity = 0,
	};

	int err = nrf_modem_dect_phy_rx(&rx);

	if (err) {
		LOG_WRN("listen failed to start: %d", err);
		return err;
	}

	s_stats.listen_windows++;

	/*
	 * Wait for the window to elapse. The generous margin is because the
	 * modem reports completion only after the whole duration, and a video
	 * fragment must not be queued while the receiver still owns the radio.
	 */
	if (k_sem_take(&op_sem, K_MSEC(ms + 200)) != 0) {
		LOG_WRN("listen window did not complete");
		return -ETIMEDOUT;
	}
	return 0;
}

void radio_set_ctrl_cb(radio_ctrl_cb_t cb)
{
	s_ctrl_cb = cb;
}

uint16_t radio_device_id(void)
{
	return s_device_id;
}

void radio_get_cfg(struct radio_cfg *out)
{
	if (out) {
		*out = s_cfg;
	}
}

int radio_set_tx_power(uint8_t idx)
{
	/*
	 * The header field is 4 bits. Which indices map to which dBm depends
	 * on the band and the modem firmware, so the only check worth making
	 * here is that it fits.
	 */
	if (idx > 15) {
		return -EINVAL;
	}
	s_cfg.tx_power = idx;
	LOG_INF("tx power index -> %u", idx);
	return 0;
}

int radio_set_mcs(uint8_t mcs)
{
	const int tbs = dectcam_tbs_bytes_subslots(mcs, s_cfg.subslots);

	if (tbs < 0) {
		LOG_WRN("MCS %u is not valid with %u subslots", mcs, s_cfg.subslots);
		return -EINVAL;
	}
	if (tbs <= (int)DECTCAM_OVERHEAD) {
		return -EINVAL;
	}

	/*
	 * Refuse a transport block that cannot carry the fragments the camera
	 * is currently producing. Accepting it would leave every transmit
	 * failing with -EINVAL and the link silently dead; the caller can lower
	 * the fragment size first and try again.
	 */
	if (tbs < (int)(s_cfg.frag_payload + DECTCAM_OVERHEAD)) {
		LOG_WRN("MCS %u gives a %d B block, too small for %u B fragments",
			mcs, tbs, s_cfg.frag_payload);
		return -EINVAL;
	}

	s_cfg.mcs = mcs;
	s_cfg.tbs_bytes = (uint16_t)tbs;
	LOG_INF("MCS -> %u (%d B transport block)", mcs, tbs);
	return 0;
}

int radio_set_carrier(uint16_t carrier)
{
	if (carrier == 0) {
		return -EINVAL;
	}
	s_cfg.carrier = carrier;
	LOG_INF("carrier -> %u", carrier);
	return 0;
}

void radio_get_stats(struct radio_stats *out)
{
	if (out) {
		*out = s_stats;
	}
}
```

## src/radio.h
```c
/*
 * radio.h - DECT NR+ PHY wrapper for the transmitter.
 *
 * SPDX-License-Identifier: Apache-2.0
 */

#ifndef DECTCAM_RADIO_H
#define DECTCAM_RADIO_H

#include <stdint.h>
#include <stddef.h>

/* Bring up the modem, the DECT PHY, and activate the radio. Blocking. */
int radio_init(void);

/*
 * Transmit one packet. Blocks until the operation completes so the caller
 * cannot outrun the modem.
 *
 * Returns 0 on success, or a negative errno.
 */
int radio_tx(const uint8_t *data, size_t len);

/*
 * Listen for `ms` milliseconds and hand any received packet to the callback
 * registered with radio_set_ctrl_cb(). Blocking.
 *
 * The transmitter has no permanent receive path: it spends most of its time
 * pushing video, and turning the radio around costs air time. Control is rare
 * and small, so the caller opens a short window between video bursts instead.
 * The other end therefore has to repeat a telegram for as long as one window
 * period, which is why control frames carry a sequence number.
 */
int radio_listen(uint32_t ms);

/* Called from the modem callback for every packet received while listening. */
typedef void (*radio_ctrl_cb_t)(const uint8_t *data, size_t len);
void radio_set_ctrl_cb(radio_ctrl_cb_t cb);

uint16_t radio_device_id(void);

/*
 * Live radio parameters.
 *
 * These start at their Kconfig values and can be changed at run time from the
 * receiver. Carrier is the delicate one: both ends must move together, so it
 * is not changed here directly -- see ctrl.c for the sequence that does it.
 */
struct radio_cfg {
	uint16_t carrier;
	uint8_t mcs;
	uint8_t tx_power;
	uint8_t subslots;
	uint16_t tbs_bytes;      /* transport block for the current mcs/subslots */
	uint16_t frag_payload;   /* tbs_bytes minus the protocol overhead        */
};

void radio_get_cfg(struct radio_cfg *out);

/*
 * Apply a new value. Each returns 0, or -EINVAL if the value is out of range
 * or the resulting transport block could not carry the fragments in use.
 */
int radio_set_tx_power(uint8_t idx);
int radio_set_mcs(uint8_t mcs);
int radio_set_carrier(uint16_t carrier);

struct radio_stats {
	uint32_t tx_ok;
	uint32_t tx_err;
	uint32_t tx_lbt_busy;
	uint64_t tx_bytes;
	uint32_t ctrl_rx;        /* control packets received while listening */
	uint32_t listen_windows;
};

void radio_get_stats(struct radio_stats *out);

#endif /* DECTCAM_RADIO_H */
```

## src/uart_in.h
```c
/*
 * uart_in.h - buffered UART reception from the camera board.
 *
 * SPDX-License-Identifier: Apache-2.0
 */

#ifndef DECTCAM_UART_IN_H
#define DECTCAM_UART_IN_H

#include <stdint.h>
#include <stddef.h>

int uart_in_init(void);

/*
 * Pop one complete, CRC-verified packet into `out`.
 *
 * Blocks up to `timeout_ms` for a packet to become available.
 * Returns the packet length, 0 on timeout, or negative on error.
 */
int uart_in_get_packet(uint8_t *out, size_t cap, int timeout_ms);

struct uart_in_stats {
	uint32_t packets;
	uint32_t crc_err;
	uint32_t resyncs;
	uint32_t overruns; /* ring buffer overflowed, bytes discarded */
	uint64_t bytes;
};

/*
 * Send one newline-terminated line to the camera on the same UART.
 *
 * Lives here rather than in camctl.c because this module owns the device and
 * its callback, and the transmit has to use the async API: mixing
 * uart_poll_out() with an active uart_rx_enable() on the nRF UARTE drops
 * characters.
 *
 * Blocks until the line is on the wire. Returns 0, or a negative errno.
 */
int uart_in_send_line(const char *line);

void uart_in_get_stats(struct uart_in_stats *out);

#endif /* DECTCAM_UART_IN_H */
```
